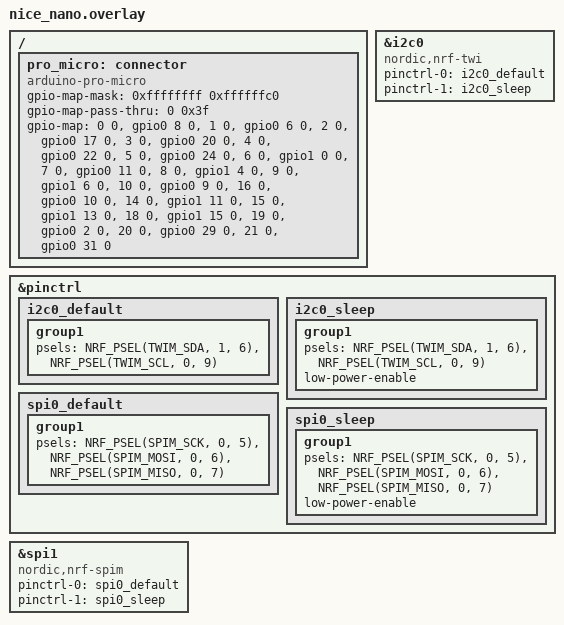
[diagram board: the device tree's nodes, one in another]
/*
 * Copyright (c) 2021 The ZMK Contributors
 *
 * SPDX-License-Identifier: MIT
 */

/ {
    pro_micro: connector {
        compatible = "arduino-pro-micro";
        #gpio-cells = <2>;
        gpio-map-mask = <0xffffffff 0xffffffc0>;
        gpio-map-pass-thru = <0 0x3f>;
        gpio-map
            = <0 0 &gpio0 8 0>      /* D0 */
            , <1 0 &gpio0 6 0>      /* D1 */
            , <2 0 &gpio0 17 0>     /* D2 */
            , <3 0 &gpio0 20 0>     /* D3 */
            , <4 0 &gpio0 22 0>     /* D4/A6 */
            , <5 0 &gpio0 24 0>     /* D5 */
            , <6 0 &gpio1 0 0>      /* D6/A7 */
            , <7 0 &gpio0 11 0>     /* D7 */
            , <8 0 &gpio1 4 0>      /* D8/A8 */
            , <9 0 &gpio1 6 0>      /* D9/A9 */
            , <10 0 &gpio0 9 0>     /* D10/A10 */
            , <16 0 &gpio0 10 0>    /* D16 */
            , <14 0 &gpio1 11 0>    /* D14 */
            , <15 0 &gpio1 13 0>    /* D15 */
            , <18 0 &gpio1 15 0>    /* D18/A0 */
            , <19 0 &gpio0 2 0>     /* D19/A1 */
            , <20 0 &gpio0 29 0>    /* D20/A2 */
            , <21 0 &gpio0 31 0>    /* D21/A3 */
            ;
    };
};

&i2c0 {
    compatible = "nordic,nrf-twi";
    status = "okay";
    pinctrl-0 = <&i2c0_default>;
    pinctrl-1 = <&i2c0_sleep>;
    pinctrl-names = "default", "sleep";
};

&pinctrl {
    i2c0_default: i2c0_default {
        group1 {
            psels = <NRF_PSEL(TWIM_SDA, 1, 6)>,  /* Pin 9 (P1.6) for SDA */
                  <NRF_PSEL(TWIM_SCL, 0, 9)>; /* Pin 10 (P0.9) for SCL */
        };
    };

    i2c0_sleep: i2c0_sleep {
        group1 {
            psels = <NRF_PSEL(TWIM_SDA, 1, 6)>,
                  <NRF_PSEL(TWIM_SCL, 0, 9)>;
            low-power-enable;
        };
    };

    spi0_default: spi0_default {
        group1 {
            psels = <NRF_PSEL(SPIM_SCK, 0, 5)>,
                <NRF_PSEL(SPIM_MOSI, 0, 6)>,
                <NRF_PSEL(SPIM_MISO, 0, 7)>;
        };
    };

    spi0_sleep: spi0_sleep {
        group1 {
            psels = <NRF_PSEL(SPIM_SCK, 0, 5)>,
                <NRF_PSEL(SPIM_MOSI, 0, 6)>,
                <NRF_PSEL(SPIM_MISO, 0, 7)>;
            low-power-enable;
        };
    };
};

&spi1 {
    compatible = "nordic,nrf-spim";
    status = "okay";
    pinctrl-0 = <&spi0_default>;
    pinctrl-1 = <&spi0_sleep>;
    pinctrl-names = "default", "sleep";
};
